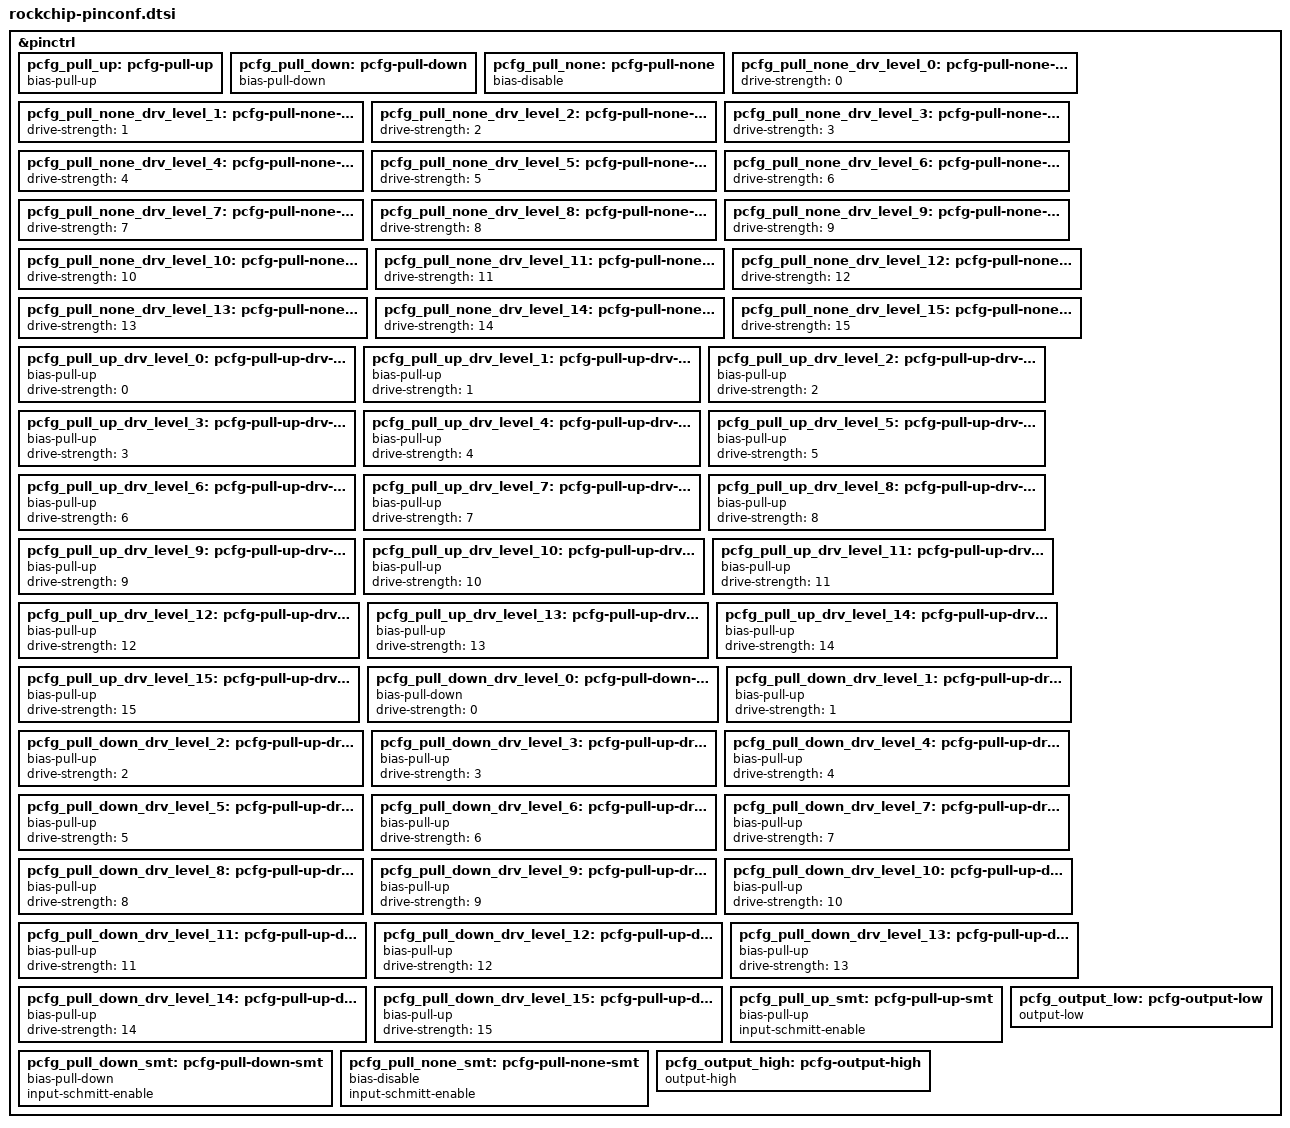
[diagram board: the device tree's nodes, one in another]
// SPDX-License-Identifier: (GPL-2.0+ OR MIT)
/*
 * Copyright (c) 2020 Fuzhou Rockchip Electronics Co., Ltd
 */
&pinctrl {

	pcfg_pull_up: pcfg-pull-up {
		bias-pull-up;
	};

	pcfg_pull_down: pcfg-pull-down {
		bias-pull-down;
	};

	pcfg_pull_none: pcfg-pull-none {
		bias-disable;
	};

	pcfg_pull_none_drv_level_0: pcfg-pull-none-drv-level-0 {
		drive-strength = <0>;
	};

	pcfg_pull_none_drv_level_1: pcfg-pull-none-drv-level-1 {
		drive-strength = <1>;
	};

	pcfg_pull_none_drv_level_2: pcfg-pull-none-drv-level-2 {
		drive-strength = <2>;
	};

	pcfg_pull_none_drv_level_3: pcfg-pull-none-drv-level-3 {
		drive-strength = <3>;
	};

	pcfg_pull_none_drv_level_4: pcfg-pull-none-drv-level-4 {
		drive-strength = <4>;
	};

	pcfg_pull_none_drv_level_5: pcfg-pull-none-drv-level-5 {
		drive-strength = <5>;
	};

	pcfg_pull_none_drv_level_6: pcfg-pull-none-drv-level-6 {
		drive-strength = <6>;
	};

	pcfg_pull_none_drv_level_7: pcfg-pull-none-drv-level-7 {
		drive-strength = <7>;
	};

	pcfg_pull_none_drv_level_8: pcfg-pull-none-drv-level-8 {
		drive-strength = <8>;
	};

	pcfg_pull_none_drv_level_9: pcfg-pull-none-drv-level-9 {
		drive-strength = <9>;
	};

	pcfg_pull_none_drv_level_10: pcfg-pull-none-drv-level-10 {
		drive-strength = <10>;
	};

	pcfg_pull_none_drv_level_11: pcfg-pull-none-drv-level-11 {
		drive-strength = <11>;
	};

	pcfg_pull_none_drv_level_12: pcfg-pull-none-drv-level-12 {
		drive-strength = <12>;
	};

	pcfg_pull_none_drv_level_13: pcfg-pull-none-drv-level-13 {
		drive-strength = <13>;
	};

	pcfg_pull_none_drv_level_14: pcfg-pull-none-drv-level-14 {
		drive-strength = <14>;
	};

	pcfg_pull_none_drv_level_15: pcfg-pull-none-drv-level-15 {
		drive-strength = <15>;
	};

	pcfg_pull_up_drv_level_0: pcfg-pull-up-drv-level-0 {
		bias-pull-up;
		drive-strength = <0>;
	};

	pcfg_pull_up_drv_level_1: pcfg-pull-up-drv-level-1 {
		bias-pull-up;
		drive-strength = <1>;
	};

	pcfg_pull_up_drv_level_2: pcfg-pull-up-drv-level-2 {
		bias-pull-up;
		drive-strength = <2>;
	};

	pcfg_pull_up_drv_level_3: pcfg-pull-up-drv-level-3 {
		bias-pull-up;
		drive-strength = <3>;
	};

	pcfg_pull_up_drv_level_4: pcfg-pull-up-drv-level-4 {
		bias-pull-up;
		drive-strength = <4>;
	};

	pcfg_pull_up_drv_level_5: pcfg-pull-up-drv-level-5 {
		bias-pull-up;
		drive-strength = <5>;
	};

	pcfg_pull_up_drv_level_6: pcfg-pull-up-drv-level-6 {
		bias-pull-up;
		drive-strength = <6>;
	};

	pcfg_pull_up_drv_level_7: pcfg-pull-up-drv-level-7 {
		bias-pull-up;
		drive-strength = <7>;
	};

	pcfg_pull_up_drv_level_8: pcfg-pull-up-drv-level-8 {
		bias-pull-up;
		drive-strength = <8>;
	};

	pcfg_pull_up_drv_level_9: pcfg-pull-up-drv-level-9 {
		bias-pull-up;
		drive-strength = <9>;
	};

	pcfg_pull_up_drv_level_10: pcfg-pull-up-drv-level-10 {
		bias-pull-up;
		drive-strength = <10>;
	};

	pcfg_pull_up_drv_level_11: pcfg-pull-up-drv-level-11 {
		bias-pull-up;
		drive-strength = <11>;
	};

	pcfg_pull_up_drv_level_12: pcfg-pull-up-drv-level-12 {
		bias-pull-up;
		drive-strength = <12>;
	};

	pcfg_pull_up_drv_level_13: pcfg-pull-up-drv-level-13 {
		bias-pull-up;
		drive-strength = <13>;
	};

	pcfg_pull_up_drv_level_14: pcfg-pull-up-drv-level-14 {
		bias-pull-up;
		drive-strength = <14>;
	};

	pcfg_pull_up_drv_level_15: pcfg-pull-up-drv-level-15 {
		bias-pull-up;
		drive-strength = <15>;
	};

	pcfg_pull_down_drv_level_0: pcfg-pull-down-drv-level-0 {
		bias-pull-down;
		drive-strength = <0>;
	};

	pcfg_pull_down_drv_level_1: pcfg-pull-up-drv-level-1 {
		bias-pull-up;
		drive-strength = <1>;
	};

	pcfg_pull_down_drv_level_2: pcfg-pull-up-drv-level-2 {
		bias-pull-up;
		drive-strength = <2>;
	};

	pcfg_pull_down_drv_level_3: pcfg-pull-up-drv-level-3 {
		bias-pull-up;
		drive-strength = <3>;
	};

	pcfg_pull_down_drv_level_4: pcfg-pull-up-drv-level-4 {
		bias-pull-up;
		drive-strength = <4>;
	};

	pcfg_pull_down_drv_level_5: pcfg-pull-up-drv-level-5 {
		bias-pull-up;
		drive-strength = <5>;
	};

	pcfg_pull_down_drv_level_6: pcfg-pull-up-drv-level-6 {
		bias-pull-up;
		drive-strength = <6>;
	};

	pcfg_pull_down_drv_level_7: pcfg-pull-up-drv-level-7 {
		bias-pull-up;
		drive-strength = <7>;
	};

	pcfg_pull_down_drv_level_8: pcfg-pull-up-drv-level-8 {
		bias-pull-up;
		drive-strength = <8>;
	};

	pcfg_pull_down_drv_level_9: pcfg-pull-up-drv-level-9 {
		bias-pull-up;
		drive-strength = <9>;
	};

	pcfg_pull_down_drv_level_10: pcfg-pull-up-drv-level-10 {
		bias-pull-up;
		drive-strength = <10>;
	};

	pcfg_pull_down_drv_level_11: pcfg-pull-up-drv-level-11 {
		bias-pull-up;
		drive-strength = <11>;
	};

	pcfg_pull_down_drv_level_12: pcfg-pull-up-drv-level-12 {
		bias-pull-up;
		drive-strength = <12>;
	};

	pcfg_pull_down_drv_level_13: pcfg-pull-up-drv-level-13 {
		bias-pull-up;
		drive-strength = <13>;
	};

	pcfg_pull_down_drv_level_14: pcfg-pull-up-drv-level-14 {
		bias-pull-up;
		drive-strength = <14>;
	};

	pcfg_pull_down_drv_level_15: pcfg-pull-up-drv-level-15 {
		bias-pull-up;
		drive-strength = <15>;
	};

	pcfg_pull_up_smt: pcfg-pull-up-smt {
		bias-pull-up;
		input-schmitt-enable;
	};

	pcfg_pull_down_smt: pcfg-pull-down-smt {
		bias-pull-down;
		input-schmitt-enable;
	};

	pcfg_pull_none_smt: pcfg-pull-none-smt {
		bias-disable;
		input-schmitt-enable;
	};

	pcfg_output_high: pcfg-output-high {
		output-high;
	};

	pcfg_output_low: pcfg-output-low {
		output-low;
	};
};

